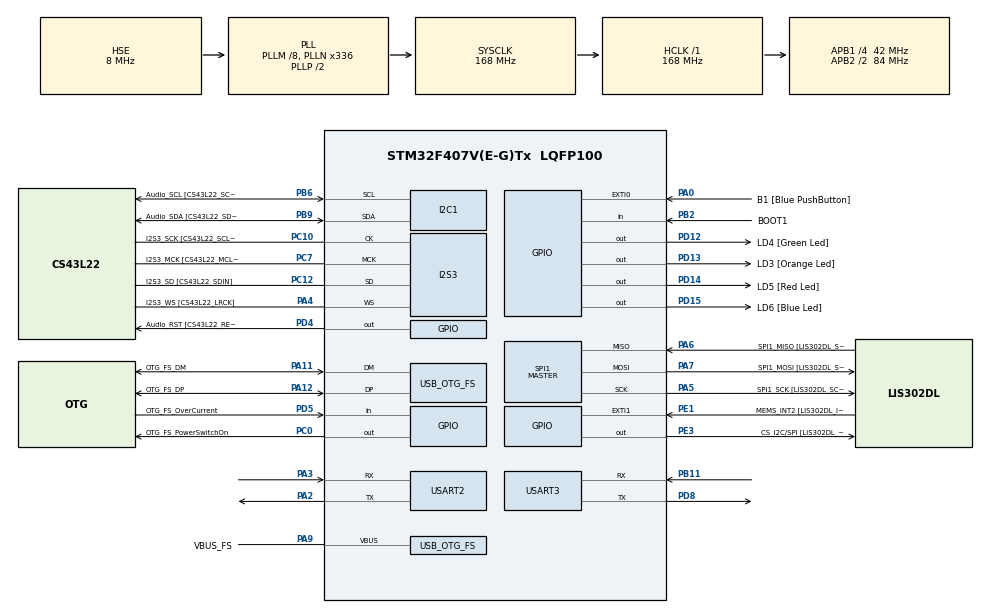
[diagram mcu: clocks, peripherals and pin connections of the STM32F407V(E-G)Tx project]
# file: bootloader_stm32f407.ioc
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I2S3.AudioFreq-Half_Duplex_Master=I2S_AUDIOFREQ_96K
I2S3.ErrorAudioFreq=-2.34 %
I2S3.ErrorAudioFreq-Half_Duplex_Master=0.8 %
I2S3.FullDuplexMode=I2S_FULLDUPLEXMODE_DISABLE
I2S3.Instance=SPI$Index
I2S3.RealAudioFreq=93.75 KHz
I2S3.RealAudioFreq-Half_Duplex_Master=96.774 KHz
I2S3.VirtualMode=I2S_MODE_MASTER
Mcu.Family=STM32F4
Mcu.Name=STM32F407V(E-G)Tx
Mcu.Package=LQFP100
NVIC.OTG_FS_IRQn=true\:0\:0\:false\:false\:true\:true\:true
NVIC.PriorityGroup=NVIC_PRIORITYGROUP_0
PA0-WKUP.GPIO_Label=B1 [Blue PushButton]
PA0-WKUP.GPIO_ModeDefaultEXTI=GPIO_MODE_EVT_RISING
PA0-WKUP.GPIO_PuPd=GPIO_NOPULL
PA0-WKUP.Signal=GPXTI0
PA10.GPIO_Label=OTG_FS_ID
PA10.GPIO_Mode=GPIO_MODE_AF_PP
PA10.GPIO_PuPd=GPIO_NOPULL
PA10.GPIO_Speed=GPIO_SPEED_FREQ_LOW
PA10.Signal=USB_OTG_FS_ID
PA11.GPIO_Label=OTG_FS_DM
PA11.GPIO_Mode=GPIO_MODE_AF_PP
PA11.GPIO_PuPd=GPIO_NOPULL
PA11.GPIO_Speed=GPIO_SPEED_FREQ_LOW
PA11.Mode=Host_Only
PA11.Signal=USB_OTG_FS_DM
PA12.GPIO_Label=OTG_FS_DP
PA12.GPIO_Mode=GPIO_MODE_AF_PP
PA12.GPIO_PuPd=GPIO_NOPULL
PA12.GPIO_Speed=GPIO_SPEED_FREQ_LOW
PA12.Mode=Host_Only
PA12.Signal=USB_OTG_FS_DP
PA13.GPIO_Label=SWDIO
PA13.Mode=Serial_Wire
PA13.Signal=SYS_JTMS-SWDIO
PA14.GPIO_Label=SWCLK
PA14.Mode=Serial_Wire
PA14.Signal=SYS_JTCK-SWCLK
PA2.Mode=Asynchronous
PA2.Signal=USART2_TX
PA3.Mode=Asynchronous
PA3.Signal=USART2_RX
PA4.GPIO_Label=I2S3_WS [CS43L22_LRCK]
PA4.GPIO_Mode=GPIO_MODE_AF_PP
PA4.GPIO_PuPd=GPIO_NOPULL
PA4.GPIO_Speed=GPIO_SPEED_FREQ_LOW
PA4.Mode=Half_Duplex_Master
PA4.Signal=I2S3_WS
PA5.GPIO_Label=SPI1_SCK [LIS302DL_SCL/SPC]
PA5.GPIO_Mode=GPIO_MODE_AF_PP
PA5.GPIO_PuPd=GPIO_NOPULL
PA5.GPIO_Speed=GPIO_SPEED_FREQ_LOW
PA5.Mode=Full_Duplex_Master
PA5.Signal=SPI1_SCK
PA6.GPIO_Label=SPI1_MISO [LIS302DL_SDO]
PA6.GPIO_Mode=GPIO_MODE_AF_PP
PA6.GPIO_PuPd=GPIO_NOPULL
PA6.GPIO_Speed=GPIO_SPEED_FREQ_LOW
PA6.Mode=Full_Duplex_Master
PA6.Signal=SPI1_MISO
PA7.GPIO_Label=SPI1_MOSI [LIS302DL_SDA/SDI/SDO]
PA7.GPIO_Mode=GPIO_MODE_AF_PP
PA7.GPIO_PuPd=GPIO_NOPULL
PA7.GPIO_Speed=GPIO_SPEED_FREQ_LOW
PA7.Mode=Full_Duplex_Master
PA7.Signal=SPI1_MOSI
PA9.GPIO_Label=VBUS_FS
PA9.GPIO_Mode=GPIO_MODE_INPUT
PA9.GPIO_PuPd=GPIO_NOPULL
PA9.Mode=Activate_VBUS
PA9.Signal=USB_OTG_FS_VBUS
PB10.GPIO_Label=CLK_IN [MP45DT02_CLK]
PB10.GPIO_Mode=GPIO_MODE_AF_PP
PB10.GPIO_PuPd=GPIO_NOPULL
PB10.GPIO_Speed=GPIO_SPEED_FREQ_LOW
PB10.Signal=I2S2_CK
PB11.Mode=Asynchronous
PB11.Signal=USART3_RX
PB2.GPIO_Label=BOOT1
PB2.GPIO_Mode=GPIO_MODE_INPUT
PB2.GPIO_PuPd=GPIO_NOPULL
PB2.Signal=GPIO_Input
PB3.GPIO_Label=SWO
PB3.Signal=SYS_JTDO-SWO
PB6.GPIO_Label=Audio_SCL [CS43L22_SCL]
PB6.GPIO_Mode=GPIO_MODE_AF_OD
PB6.GPIO_Pu=GPIO_PULLUP
PB6.GPIO_PuPd=GPIO_NOPULL
PB6.GPIO_Speed=GPIO_SPEED_FREQ_LOW
PB6.Mode=I2C
PB6.Signal=I2C1_SCL
PB9.GPIO_Label=Audio_SDA [CS43L22_SDA]
PB9.GPIO_Mode=GPIO_MODE_AF_OD
PB9.GPIO_Pu=GPIO_PULLUP
PB9.GPIO_PuPd=GPIO_NOPULL
PB9.GPIO_Speed=GPIO_SPEED_FREQ_LOW
PB9.Mode=I2C
PB9.Signal=I2C1_SDA
PC0.GPIO_Label=OTG_FS_PowerSwitchOn
PC0.GPIO_PuPd=GPIO_NOPULL
PC0.GPIO_Speed=GPIO_SPEED_FREQ_LOW
PC0.PinState=GPIO_PIN_SET
PC0.Signal=GPIO_Output
PC10.GPIO_Label=I2S3_SCK [CS43L22_SCLK]
PC10.GPIO_Mode=GPIO_MODE_AF_PP
PC10.GPIO_PuPd=GPIO_NOPULL
PC10.GPIO_Speed=GPIO_SPEED_FREQ_LOW
PC10.Mode=Half_Duplex_Master
PC10.Signal=I2S3_CK
PC12.GPIO_Label=I2S3_SD [CS43L22_SDIN]
PC12.GPIO_Mode=GPIO_MODE_AF_PP
PC12.GPIO_PuPd=GPIO_NOPULL
PC12.GPIO_Speed=GPIO_SPEED_FREQ_LOW
PC12.Mode=Half_Duplex_Master
PC12.Signal=I2S3_SD
PC14-OSC32_IN.GPIO_Label=PC14-OSC32_IN
PC14-OSC32_IN.Mode=LSE-External-Oscillator
PC14-OSC32_IN.Signal=RCC_OSC32_IN
PC15-OSC32_OUT.GPIO_Label=PC15-OSC32_OUT
PC15-OSC32_OUT.Mode=LSE-External-Oscillator
PC15-OSC32_OUT.Signal=RCC_OSC32_OUT
PC3.GPIO_Label=PDM_OUT [MP45DT02_DOUT]
PC3.GPIO_Mode=GPIO_MODE_AF_PP
PC3.GPIO_PuPd=GPIO_NOPULL
PC3.GPIO_Speed=GPIO_SPEED_FREQ_LOW
PC3.Signal=I2S2_SD
PC7.GPIO_Label=I2S3_MCK [CS43L22_MCLK]
PC7.GPIO_Mode=GPIO_MODE_AF_PP
PC7.GPIO_PuPd=GPIO_NOPULL
PC7.GPIO_Speed=GPIO_SPEED_FREQ_LOW
PC7.Mode=Master_Clock_Activated
PC7.Signal=I2S3_MCK
PD12.GPIO_Label=LD4 [Green Led]
PD12.GPIO_PuPd=GPIO_NOPULL
PD12.GPIO_Speed=GPIO_SPEED_FREQ_LOW
PD12.Signal=GPIO_Output
PD13.GPIO_Label=LD3 [Orange Led]
PD13.GPIO_PuPd=GPIO_NOPULL
PD13.GPIO_Speed=GPIO_SPEED_FREQ_LOW
PD13.Signal=GPIO_Output
PD14.GPIO_Label=LD5 [Red Led]
PD14.GPIO_PuPd=GPIO_NOPULL
PD14.GPIO_Speed=GPIO_SPEED_FREQ_LOW
PD14.Signal=GPIO_Output
PD15.GPIO_Label=LD6 [Blue Led]
PD15.GPIO_PuPd=GPIO_NOPULL
PD15.GPIO_Speed=GPIO_SPEED_FREQ_LOW
PD15.Signal=GPIO_Output
PD4.GPIO_Label=Audio_RST [CS43L22_RESET]
PD4.GPIO_PuPd=GPIO_NOPULL
PD4.GPIO_Speed=GPIO_SPEED_FREQ_LOW
PD4.Signal=GPIO_Output
PD5.GPIO_Label=OTG_FS_OverCurrent
PD5.GPIO_Mode=GPIO_MODE_INPUT
PD5.GPIO_PuPd=GPIO_NOPULL
PD5.Signal=GPIO_Input
PD8.Mode=Asynchronous
PD8.Signal=USART3_TX
PE1.GPIO_Label=MEMS_INT2 [LIS302DL_INT2]
PE1.GPIO_ModeDefaultEXTI=GPIO_MODE_EVT_RISING
PE1.GPIO_PuPd=GPIO_NOPULL
PE1.Signal=GPXTI1
PE3.GPIO_Label=CS_I2C/SPI [LIS302DL_CS_I2C/SPI]
PE3.GPIO_PuPd=GPIO_NOPULL
PE3.GPIO_Speed=GPIO_SPEED_FREQ_LOW
PE3.Signal=GPIO_Output
PH0-OSC_IN.GPIO_Label=PH0-OSC_IN
PH0-OSC_IN.Mode=HSE-External-Oscillator
PH0-OSC_IN.Signal=RCC_OSC_IN
PH1-OSC_OUT.GPIO_Label=PH1-OSC_OUT
PH1-OSC_OUT.Mode=HSE-External-Oscillator
PH1-OSC_OUT.Signal=RCC_OSC_OUT
ProjectManager.HeapSize=0x200
ProjectManager.StackSize=0x400
ProjectManager.TargetToolchain=STM32CubeIDE
RCC.48MHZClocksFreq_Value=48000000
RCC.AHBFreq_Value=168000000
RCC.APB1CLKDivider=RCC_HCLK_DIV4
RCC.APB1Freq_Value=42000000
RCC.APB1TimFreq_Value=84000000
RCC.APB2CLKDivider=RCC_HCLK_DIV2
RCC.APB2Freq_Value=84000000
RCC.APB2TimFreq_Value=168000000
RCC.CortexFreq_Value=168000000
RCC.HCLKFreq_Value=168000000
RCC.HSE_VALUE=8000000
RCC.HSI_VALUE=16000000
RCC.PLLM=8
RCC.PLLN=336
RCC.PLLQ=7
RCC.SYSCLKFreq_VALUE=168000000
RCC.SYSCLKSource=RCC_SYSCLKSOURCE_PLLCLK
RCC.VCOOutputFreq_Value=336000000
SPI1.BaudRatePrescaler-Full_Duplex_Master=SPI_BAUDRATEPRESCALER_2
SPI1.CalculateBaudRate-Full_Duplex_Master=42.0 MBits/s
SPI1.Direction=SPI_DIRECTION_2LINES
SPI1.Mode=SPI_MODE_MASTER
SPI1.Mode-Full_Duplex_Master=SPI_MODE_MASTER
SPI1.VirtualType=VM_MASTER
USART2.VirtualMode=VM_ASYNC
USART3.VirtualMode=VM_ASYNC
USB_HOST.BSP.number=1
USB_HOST.USBH_HandleTypeDef-CDC_FS=hUsbHostFS
USB_HOST.VirtualModeFS=Cdc
USB_HOST0.BSP.STBoard=false
USB_HOST0.BSP.api=Unknown
USB_HOST0.BSP.i2caddr=0
USB_HOST0.BSP.i2creg=0
USB_HOST0.BSP.instance=PC0
USB_HOST0.BSP.ip=GPIO
USB_HOST0.BSP.mode=Output
USB_HOST0.BSP.name=Drive_VBUS_FS
USB_HOST0.BSP.solution=PC0
USB_OTG_FS.VirtualMode=Host_Only
USB_OTG_FS.phy_itface=HCD_PHY_EMBEDDED
VP_CRC_VS_CRC.Mode=CRC_Activate
VP_USB_HOST_VS_USB_HOST_CDC_FS.Mode=CDC_FS
board=STM32F407G-DISC1

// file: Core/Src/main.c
/* USER CODE BEGIN Header */
/**
  ******************************************************************************
  * @file           : main.c
  * @brief          : Main program body
  ******************************************************************************
  * @attention
  *
  * <h2><center>&copy; Copyright (c) 2021 STMicroelectronics.
  * All rights reserved.</center></h2>
  *
  * This software component is licensed by ST under Ultimate Liberty license
  * SLA0044, the "License"; You may not use this file except in compliance with
  * the License. You may obtain a copy of the License at:
  *                             www.st.com/SLA0044
  *
  ******************************************************************************
  */
/* USER CODE END Header */
#include <stdarg.h>
#include <string.h>
#include <stdio.h>
#include "main.h"
#include "usb_host.h"

/* USER CODE BEGIN PM */
#define BL_DEBUG_MSG_EN

/* USER CODE END PM */

CRC_HandleTypeDef hcrc;

I2C_HandleTypeDef hi2c1;

I2S_HandleTypeDef hi2s3;

SPI_HandleTypeDef hspi1;

UART_HandleTypeDef huart2;
UART_HandleTypeDef huart3;

uint8_t supported_commands[] = {
								BL_GET_VER,
								BL_GET_HELP,
								BL_GET_CID,
								BL_GET_RDP_STATUS,
								BL_GO_TO_ADDR,
								BL_FLASH_ERASE,
								BL_MEM_WRITE,
								BL_EN_RW_PROTECT,
								BL_MEM_READ,
								BL_READ_SECTOR_P_STATUS,
								BL_OTP_READ,
								BL_DIS_R_W_PROTECT};

#define D_UART &huart3
#define C_UART &huart2
#define BL_RX_LEN 200

void SystemClock_Config(void);
static void MX_GPIO_Init(void);
static void MX_I2C1_Init(void);
static void MX_I2S3_Init(void);
static void MX_SPI1_Init(void);
static void MX_USART2_UART_Init(void);
static void MX_USART3_UART_Init(void);
static void MX_CRC_Init(void);
void MX_USB_HOST_Process(void);

/* USER CODE BEGIN PFP */
static void printmsg(char *format, ...);

/* USER CODE END PFP */

/* USER CODE BEGIN 0 */
char somedata[] = "Hello from Bootloader\r\n";

uint8_t bl_rx_buffer[BL_RX_LEN];

/* USER CODE END 0 */

int main(void)
{

  /* MCU Configuration--------------------------------------------------------*/

  /* Reset of all peripherals, Initializes the Flash interface and the Systick. */
  HAL_Init();

  /* Configure the system clock */
  SystemClock_Config();

  /* Initialize all configured peripherals */
  MX_GPIO_Init();
  MX_I2C1_Init();
  MX_I2S3_Init();
  MX_SPI1_Init();
  MX_USB_HOST_Init();
  MX_USART2_UART_Init();
  MX_USART3_UART_Init();
  MX_CRC_Init();

  /* Let's check whether button is pressed or not, if not pressed jump to user application */
  if (HAL_GPIO_ReadPin(B1_GPIO_Port, B1_Pin) == GPIO_PIN_SET)
  {
	  printmsg("BL_DEBUG_MSG:Button is pressed....going to BL mode\r\n");
	  // we should continue in bootloader mode
	  bootloader_uart_read_data();
  }
  else
  {
	  printmsg("BL_DEBUG_MSG:Button is not pressed....going to app mode\r\n");

	  // we should continue in app mode
	  bootloader_jump_to_app();
  }
}

void bootloader_uart_read_data(void)
{
	uint8_t rcv_len = 0;
	while(1)
	{
		memset(bl_rx_buffer, 0, 200);
		// Here we will read and decode the commands coming from host
		// first read only one byte from the host, which is the length field
		HAL_UART_Receive(C_UART, bl_rx_buffer, 1, HAL_MAX_DELAY);
		rcv_len = (uint8_t) bl_rx_buffer[0];
		HAL_UART_Receive(C_UART, &bl_rx_buffer[1], rcv_len, HAL_MAX_DELAY);
		switch(bl_rx_buffer[1])
		{
			case BL_GET_VER:
				bootloader_handle_getver_cmd(bl_rx_buffer);
				break;
			case BL_GET_HELP:
				bootloader_handle_gethelp_cmd(bl_rx_buffer);
				break;
			case BL_GET_CID:
				bootloader_handle_getcid_cmd(bl_rx_buffer);
				break;
			case BL_GET_RDP_STATUS:
				bootloader_handle_getrdp_cmd(bl_rx_buffer);
				break;
			case BL_GO_TO_ADDR:
				bootloader_handle_go_cmd(bl_rx_buffer);
				break;
			case BL_FLASH_ERASE:
				bootloader_handle_flash_erase_cmd(bl_rx_buffer);
				break;
			case BL_MEM_WRITE:
				bootloader_handle_mem_write_cmd(bl_rx_buffer);
				break;
			case BL_EN_RW_PROTECT:
				bootloader_handle_en_rw_protect(bl_rx_buffer);
				break;
			case BL_DIS_R_W_PROTECT:
                bootloader_handle_dis_rw_protect(bl_rx_buffer);
			case BL_MEM_READ:
				bootloader_handle_mem_read(bl_rx_buffer);
				break;
			case BL_READ_SECTOR_P_STATUS:
				bootloader_handle_read_sector_protection_status(bl_rx_buffer);
				break;
			default:
				printmsg("BL_DEBUG_MSG:Invalid command received from host \n");
				break;
		}
	}
}

void bootloader_jump_to_app(void){
	// just a function pointer to hold the address of the reset handler of the user app
	void (*app_reset_handler)(void);

	printmsg("BL_DEBUG_MSG:bootloader_jump_to_app\r\n");

//	__disable_irq();
	// 1. configure the MSP by reading the value from the base address of the sector 2
	uint32_t msp_value = *(__IO uint32_t *) FLASH_SECTOR2_BASE_ADDRESS;

	// This function comes from CMSIS
	__set_MSP(msp_value);

	// SCB->VTOR = FLASH_SECTOR1_BASE_ADDRESS

	// 2. Now fetch the reset handler address of the user application from the location FLASH_SECTOR2_BASE_ADDRESS
	uint32_t resethandler_address = *(__IO uint32_t *) (FLASH_SECTOR2_BASE_ADDRESS + 4);

	app_reset_handler = (void (*) (void)) resethandler_address;

	printmsg("BL_DEBUG_MSG:app reset handler address: %#x\r\n", app_reset_handler);

//	__enable_irq();
	// 3. Jump to reset handler of the application
	app_reset_handler();
}

/* prints formatted string to console over UART */
void printmsg(char *format, ...)
{
#ifdef BL_DEBUG_MSG_EN
	char str[80];
	/*Extract the argument list using VA pins */
	va_list args;
	va_start(args, format);
	vsprintf(str, format, args);
	HAL_UART_Transmit(D_UART, (uint8_t *) str, strlen(str), HAL_MAX_DELAY);
	va_end(args);
#endif
}

void SystemClock_Config(void)
{
  RCC_OscInitTypeDef RCC_OscInitStruct = {0};
  RCC_ClkInitTypeDef RCC_ClkInitStruct = {0};

  /** Configure the main internal regulator output voltage
  */
  __HAL_RCC_PWR_CLK_ENABLE();
  __HAL_PWR_VOLTAGESCALING_CONFIG(PWR_REGULATOR_VOLTAGE_SCALE1);
  /** Initializes the RCC Oscillators according to the specified parameters
  * in the RCC_OscInitTypeDef structure.
  */
  RCC_OscInitStruct.OscillatorType = RCC_OSCILLATORTYPE_HSE;
  RCC_OscInitStruct.HSEState = RCC_HSE_ON;
  RCC_OscInitStruct.PLL.PLLState = RCC_PLL_ON;
  RCC_OscInitStruct.PLL.PLLSource = RCC_PLLSOURCE_HSE;
  RCC_OscInitStruct.PLL.PLLM = 8;
  RCC_OscInitStruct.PLL.PLLN = 336;
  RCC_OscInitStruct.PLL.PLLP = RCC_PLLP_DIV2;
  RCC_OscInitStruct.PLL.PLLQ = 7;
  if (HAL_RCC_OscConfig(&RCC_OscInitStruct) != HAL_OK)
  {
    Error_Handler();
  }
  /** Initializes the CPU, AHB and APB buses clocks
  */
  RCC_ClkInitStruct.ClockType = RCC_CLOCKTYPE_HCLK|RCC_CLOCKTYPE_SYSCLK
                              |RCC_CLOCKTYPE_PCLK1|RCC_CLOCKTYPE_PCLK2;
  RCC_ClkInitStruct.SYSCLKSource = RCC_SYSCLKSOURCE_PLLCLK;
  RCC_ClkInitStruct.AHBCLKDivider = RCC_SYSCLK_DIV1;
  RCC_ClkInitStruct.APB1CLKDivider = RCC_HCLK_DIV4;
  RCC_ClkInitStruct.APB2CLKDivider = RCC_HCLK_DIV2;

  if (HAL_RCC_ClockConfig(&RCC_ClkInitStruct, FLASH_LATENCY_5) != HAL_OK)
  {
    Error_Handler();
  }
}

static void MX_CRC_Init(void)
{

  hcrc.Instance = CRC;
  if (HAL_CRC_Init(&hcrc) != HAL_OK)
  {
    Error_Handler();
  }

}

static void MX_I2C1_Init(void)
{

  hi2c1.Instance = I2C1;
  hi2c1.Init.ClockSpeed = 100000;
  hi2c1.Init.DutyCycle = I2C_DUTYCYCLE_2;
  hi2c1.Init.OwnAddress1 = 0;
  hi2c1.Init.AddressingMode = I2C_ADDRESSINGMODE_7BIT;
  hi2c1.Init.DualAddressMode = I2C_DUALADDRESS_DISABLE;
  hi2c1.Init.OwnAddress2 = 0;
  hi2c1.Init.GeneralCallMode = I2C_GENERALCALL_DISABLE;
  hi2c1.Init.NoStretchMode = I2C_NOSTRETCH_DISABLE;
  if (HAL_I2C_Init(&hi2c1) != HAL_OK)
  {
    Error_Handler();
  }

}

static void MX_I2S3_Init(void)
{

  hi2s3.Instance = SPI3;
  hi2s3.Init.Mode = I2S_MODE_MASTER_TX;
  hi2s3.Init.Standard = I2S_STANDARD_PHILIPS;
  hi2s3.Init.DataFormat = I2S_DATAFORMAT_16B;
  hi2s3.Init.MCLKOutput = I2S_MCLKOUTPUT_ENABLE;
  hi2s3.Init.AudioFreq = I2S_AUDIOFREQ_96K;
  hi2s3.Init.CPOL = I2S_CPOL_LOW;
  hi2s3.Init.ClockSource = I2S_CLOCK_PLL;
  hi2s3.Init.FullDuplexMode = I2S_FULLDUPLEXMODE_DISABLE;
  if (HAL_I2S_Init(&hi2s3) != HAL_OK)
  {
    Error_Handler();
  }

}

static void MX_SPI1_Init(void)
{

  /* SPI1 parameter configuration*/
  hspi1.Instance = SPI1;
  hspi1.Init.Mode = SPI_MODE_MASTER;
  hspi1.Init.Direction = SPI_DIRECTION_2LINES;
  hspi1.Init.DataSize = SPI_DATASIZE_8BIT;
  hspi1.Init.CLKPolarity = SPI_POLARITY_LOW;
  hspi1.Init.CLKPhase = SPI_PHASE_1EDGE;
  hspi1.Init.NSS = SPI_NSS_SOFT;
  hspi1.Init.BaudRatePrescaler = SPI_BAUDRATEPRESCALER_2;
  hspi1.Init.FirstBit = SPI_FIRSTBIT_MSB;
  hspi1.Init.TIMode = SPI_TIMODE_DISABLE;
  hspi1.Init.CRCCalculation = SPI_CRCCALCULATION_DISABLE;
  hspi1.Init.CRCPolynomial = 10;
  if (HAL_SPI_Init(&hspi1) != HAL_OK)
  {
    Error_Handler();
  }

}

static void MX_USART2_UART_Init(void)
{

  huart2.Instance = USART2;
  huart2.Init.BaudRate = 115200;
  huart2.Init.WordLength = UART_WORDLENGTH_8B;
  huart2.Init.StopBits = UART_STOPBITS_1;
  huart2.Init.Parity = UART_PARITY_NONE;
  huart2.Init.Mode = UART_MODE_TX_RX;
  huart2.Init.HwFlowCtl = UART_HWCONTROL_NONE;
  huart2.Init.OverSampling = UART_OVERSAMPLING_16;
  if (HAL_UART_Init(&huart2) != HAL_OK)
  {
    Error_Handler();
  }

}

static void MX_USART3_UART_Init(void)
{

  huart3.Instance = USART3;
  huart3.Init.BaudRate = 115200;
  huart3.Init.WordLength = UART_WORDLENGTH_8B;
  huart3.Init.StopBits = UART_STOPBITS_1;
  huart3.Init.Parity = UART_PARITY_NONE;
  huart3.Init.Mode = UART_MODE_TX_RX;
  huart3.Init.HwFlowCtl = UART_HWCONTROL_NONE;
  huart3.Init.OverSampling = UART_OVERSAMPLING_16;
  if (HAL_UART_Init(&huart3) != HAL_OK)
  {
    Error_Handler();
  }

}

static void MX_GPIO_Init(void)
{
  GPIO_InitTypeDef GPIO_InitStruct = {0};

  /* GPIO Ports Clock Enable */
  __HAL_RCC_GPIOE_CLK_ENABLE();
  __HAL_RCC_GPIOC_CLK_ENABLE();
  __HAL_RCC_GPIOH_CLK_ENABLE();
  __HAL_RCC_GPIOA_CLK_ENABLE();
  __HAL_RCC_GPIOB_CLK_ENABLE();
  __HAL_RCC_GPIOD_CLK_ENABLE();

  /*Configure GPIO pin Output Level */
  HAL_GPIO_WritePin(CS_I2C_SPI_GPIO_Port, CS_I2C_SPI_Pin, GPIO_PIN_RESET);

  /*Configure GPIO pin Output Level */
  HAL_GPIO_WritePin(OTG_FS_PowerSwitchOn_GPIO_Port, OTG_FS_PowerSwitchOn_Pin, GPIO_PIN_SET);

  /*Configure GPIO pin Output Level */
  HAL_GPIO_WritePin(GPIOD, LD4_Pin|LD3_Pin|LD5_Pin|LD6_Pin
                          |Audio_RST_Pin, GPIO_PIN_RESET);

  /*Configure GPIO pin : CS_I2C_SPI_Pin */
  GPIO_InitStruct.Pin = CS_I2C_SPI_Pin;
  GPIO_InitStruct.Mode = GPIO_MODE_OUTPUT_PP;
  GPIO_InitStruct.Pull = GPIO_NOPULL;
  GPIO_InitStruct.Speed = GPIO_SPEED_FREQ_LOW;
  HAL_GPIO_Init(CS_I2C_SPI_GPIO_Port, &GPIO_InitStruct);

  /*Configure GPIO pin : OTG_FS_PowerSwitchOn_Pin */
  GPIO_InitStruct.Pin = OTG_FS_PowerSwitchOn_Pin;
  GPIO_InitStruct.Mode = GPIO_MODE_OUTPUT_PP;
  GPIO_InitStruct.Pull = GPIO_NOPULL;
  GPIO_InitStruct.Speed = GPIO_SPEED_FREQ_LOW;
  HAL_GPIO_Init(OTG_FS_PowerSwitchOn_GPIO_Port, &GPIO_InitStruct);

  /*Configure GPIO pin : PDM_OUT_Pin */
  GPIO_InitStruct.Pin = PDM_OUT_Pin;
  GPIO_InitStruct.Mode = GPIO_MODE_AF_PP;
  GPIO_InitStruct.Pull = GPIO_NOPULL;
  GPIO_InitStruct.Speed = GPIO_SPEED_FREQ_LOW;
  GPIO_InitStruct.Alternate = GPIO_AF5_SPI2;
  HAL_GPIO_Init(PDM_OUT_GPIO_Port, &GPIO_InitStruct);

  /*Configure GPIO pin : B1_Pin */
  GPIO_InitStruct.Pin = B1_Pin;
  GPIO_InitStruct.Mode = GPIO_MODE_EVT_RISING;
  GPIO_InitStruct.Pull = GPIO_NOPULL;
  HAL_GPIO_Init(B1_GPIO_Port, &GPIO_InitStruct);

  /*Configure GPIO pin : BOOT1_Pin */
  GPIO_InitStruct.Pin = BOOT1_Pin;
  GPIO_InitStruct.Mode = GPIO_MODE_INPUT;
  GPIO_InitStruct.Pull = GPIO_NOPULL;
  HAL_GPIO_Init(BOOT1_GPIO_Port, &GPIO_InitStruct);

  /*Configure GPIO pin : CLK_IN_Pin */
  GPIO_InitStruct.Pin = CLK_IN_Pin;
  GPIO_InitStruct.Mode = GPIO_MODE_AF_PP;
  GPIO_InitStruct.Pull = GPIO_NOPULL;
  GPIO_InitStruct.Speed = GPIO_SPEED_FREQ_LOW;
  GPIO_InitStruct.Alternate = GPIO_AF5_SPI2;
  HAL_GPIO_Init(CLK_IN_GPIO_Port, &GPIO_InitStruct);

  /*Configure GPIO pins : LD4_Pin LD3_Pin LD5_Pin LD6_Pin
                           Audio_RST_Pin */
  GPIO_InitStruct.Pin = LD4_Pin|LD3_Pin|LD5_Pin|LD6_Pin
                          |Audio_RST_Pin;
  GPIO_InitStruct.Mode = GPIO_MODE_OUTPUT_PP;
  GPIO_InitStruct.Pull = GPIO_NOPULL;
  GPIO_InitStruct.Speed = GPIO_SPEED_FREQ_LOW;
  HAL_GPIO_Init(GPIOD, &GPIO_InitStruct);

  /*Configure GPIO pin : OTG_FS_OverCurrent_Pin */
  GPIO_InitStruct.Pin = OTG_FS_OverCurrent_Pin;
  GPIO_InitStruct.Mode = GPIO_MODE_INPUT;
  GPIO_InitStruct.Pull = GPIO_NOPULL;
  HAL_GPIO_Init(OTG_FS_OverCurrent_GPIO_Port, &GPIO_InitStruct);

  /*Configure GPIO pin : MEMS_INT2_Pin */
  GPIO_InitStruct.Pin = MEMS_INT2_Pin;
  GPIO_InitStruct.Mode = GPIO_MODE_EVT_RISING;
  GPIO_InitStruct.Pull = GPIO_NOPULL;
  HAL_GPIO_Init(MEMS_INT2_GPIO_Port, &GPIO_InitStruct);

}

/********* Implementation of Bootloader command handle functions *********************/
void bootloader_handle_gethelp_cmd(uint8_t *pBuffer)
{
	// 1. verify the checksum
	printmsg("BL_DEBUG_MSG: bootloader_handle_gethelp_cmd \r\n");

	// Total length of the command packet
	uint32_t command_packet_len = pBuffer[0] + 1;

	// Extract the CRC32 sent by the Host
	uint32_t host_crc = *((uint32_t *) (pBuffer + command_packet_len - 4));

	if(!bootloader_verify_crc(&pBuffer[0], command_packet_len - 4, host_crc))
	{
		printmsg("BL_DEBUG_MSG: checksum success !! \r\n");
		// checksum is correct
		bootloader_send_ack(pBuffer[0], sizeof(supported_commands));
		bootloader_uart_write_data(supported_commands, sizeof(supported_commands));
	}
	else
	{
		printmsg("BL_DEBUG_MSG: checksum fail !! \r\n");
		// checksum is wrong send neck
		bootloader_send_nack();
	}
}

void bootloader_handle_getver_cmd(uint8_t *bl_rx_buffer)
{
	uint8_t bl_version;
	printmsg("BL_DEBUG_MSG: bootloader_handle_getver_cmd \r\n");

	// Total length of the command packet
	uint32_t command_packet_len = bl_rx_buffer[0] + 1;

	// Extract the CRC32 sent by the Host
	uint32_t host_crc = *((uint32_t *) (bl_rx_buffer + command_packet_len - 4));

	if(!bootloader_verify_crc(&bl_rx_buffer[0], command_packet_len - 4, host_crc))
	{
		printmsg("BL_DEBUG_MSG:checksum success !! \r\n");
		// checksum is correct
		bootloader_send_ack(bl_rx_buffer[0], 1);
		bl_version = get_bootloader_version();
		printmsg("BL_DEBUG_MSG:BL_VER : %d %#x", bl_version, bl_version);
		bootloader_uart_write_data(&bl_version, 1);
	}
	else
	{
		printmsg("BL_DEBUG_MSG: checksum fail !! \r\n");
		// checksum is wrong send neck
		bootloader_send_nack();
	}
}

void bootloader_handle_getcid_cmd(uint8_t *pBuffer)
{
	uint16_t bl_cid_num;
	// 1. verify the checksum
	printmsg("BL_DEBUG_MSG: bootloader_handle_getcid_cmd \r\n");

	// Total length of the command packet
	uint32_t command_packet_len = pBuffer[0] + 1;

	// Extract the CRC32 sent by the Host
	uint32_t host_crc = *((uint32_t *) (pBuffer + command_packet_len - 4));

	if(!bootloader_verify_crc(&pBuffer[0], command_packet_len - 4, host_crc))
	{
		printmsg("BL_DEBUG_MSG: checksum success !! \r\n");
		// checksum is correct
		bootloader_send_ack(pBuffer[0], 2);
		bl_cid_num = get_mcu_chip_id();
		printmsg("BL_DEBUG_MSG: MCU id : %d %#x !! \r\n", bl_cid_num, bl_cid_num);
		bootloader_uart_write_data((uint8_t *) &bl_cid_num, 2);
	}
	else
	{
		printmsg("BL_DEBUG_MSG: checksum fail !! \r\n");
		// checksum is wrong send neck
		bootloader_send_nack();
	}
}

void bootloader_handle_getrdp_cmd(uint8_t *pBuffer)
{
	uint8_t rdp_level = 0x00;
	// 1. verify the checksum
	printmsg("BL_DEBUG_MSG: bootloader_handle_getrdp_cmd \r\n");

	// Total length of the command packet
	uint32_t command_packet_len = pBuffer[0] + 1;

	// Extract the CRC32 sent by the Host
	uint32_t host_crc = *((uint32_t *) (pBuffer + command_packet_len - 4));

	if(!bootloader_verify_crc(&pBuffer[0], command_packet_len - 4, host_crc))
	{
		printmsg("BL_DEBUG_MSG: checksum success !! \r\n");
		// checksum is correct
		bootloader_send_ack(pBuffer[0], 1);
		rdp_level = get_flash_rdp_level();
		printmsg("BL_DEBUG_MSG: RDP level : %d %#x !! \r\n", rdp_level, rdp_level);
		bootloader_uart_write_data(&rdp_level, 1);
	}
	else
	{
		printmsg("BL_DEBUG_MSG: checksum fail !! \r\n");
		// checksum is wrong send neck
		bootloader_send_nack();
	}

}

void bootloader_handle_go_cmd(uint8_t *pBuffer)
{
    uint32_t go_address=0;
    uint8_t addr_valid = ADDR_VALID;
    uint8_t addr_invalid = ADDR_INVALID;

    printmsg("BL_DEBUG_MSG:bootloader_handle_go_cmd\n");

    //Total length of the command packet
	uint32_t command_packet_len = pBuffer[0]+1 ;

	//extract the CRC32 sent by the Host
	uint32_t host_crc = *((uint32_t * ) (pBuffer+command_packet_len - 4) ) ;

	if (!bootloader_verify_crc(&pBuffer[0],command_packet_len-4,host_crc))
	{
        printmsg("BL_DEBUG_MSG:checksum success !!\n");

        bootloader_send_ack(pBuffer[0],1);

        //extract the go address
        go_address = *((uint32_t *)&pBuffer[2] );
        printmsg("BL_DEBUG_MSG:GO addr: %#x\n",go_address);

        if( verify_address(go_address) == ADDR_VALID )
        {
            //tell host that address is fine
            bootloader_uart_write_data(&addr_valid,1);

            /*jump to "go" address.
            we dont care what is being done there.
            host must ensure that valid code is present over there
            Its not the duty of bootloader. so just trust and jump */

            /* Not doing the below line will result in hardfault exception for ARM cortex M */
            //watch : https://www.youtube.com/watch?v=VX_12SjnNhY

//            go_address+=1; //make T bit =1

            void (*lets_jump)(void) = (void *)go_address;

            printmsg("BL_DEBUG_MSG: jumping to go address! \n");

            lets_jump();

		}else
		{
            printmsg("BL_DEBUG_MSG:GO addr invalid ! \n");
            //tell host that address is invalid
            bootloader_uart_write_data(&addr_invalid,1);
		}

	}else
	{
        printmsg("BL_DEBUG_MSG:checksum fail !!\n");
        bootloader_send_nack();
	}
}

void bootloader_handle_flash_erase_cmd(uint8_t *pBuffer)
{
    uint8_t erase_status = 0x00;
    printmsg("BL_DEBUG_MSG:bootloader_handle_flash_erase_cmd\n");

    //Total length of the command packet
	uint32_t command_packet_len = pBuffer[0]+1 ;

	//extract the CRC32 sent by the Host
	uint32_t host_crc = *((uint32_t * ) (pBuffer+command_packet_len - 4) ) ;

	if (! bootloader_verify_crc(&pBuffer[0],command_packet_len-4,host_crc))
	{
        printmsg("BL_DEBUG_MSG:checksum success !!\n");
        bootloader_send_ack(pBuffer[0],1);
        printmsg("BL_DEBUG_MSG:initial_sector : %d  no_ofsectors: %d\n",pBuffer[2],pBuffer[3]);

        HAL_GPIO_WritePin(LD3_GPIO_Port, LD3_Pin,GPIO_PIN_SET);
        erase_status = execute_flash_erase(pBuffer[2] , pBuffer[3]);
        HAL_GPIO_WritePin(LD3_GPIO_Port, LD3_Pin,GPIO_PIN_RESET);

        printmsg("BL_DEBUG_MSG: flash erase status: %#x\n",erase_status);

        bootloader_uart_write_data(&erase_status,1);

	}else
	{
        printmsg("BL_DEBUG_MSG:checksum fail !!\n");
        bootloader_send_nack();
	}

}

/*Helper function to handle BL_MEM_WRITE command */
void bootloader_handle_mem_write_cmd(uint8_t *pBuffer)
{
	uint8_t write_status = 0x00;
	uint8_t payload_len = pBuffer[6];

	uint32_t mem_address = *((uint32_t *) ( &pBuffer[2]) );

    printmsg("BL_DEBUG_MSG:bootloader_handle_mem_write_cmd\n");

    //Total length of the command packet
	uint32_t command_packet_len = pBuffer[0]+1 ;

	//extract the CRC32 sent by the Host
	uint32_t host_crc = *((uint32_t * ) (pBuffer+command_packet_len - 4) ) ;

	if (! bootloader_verify_crc(&bl_rx_buffer[0],command_packet_len-4,host_crc))
	{
        printmsg("BL_DEBUG_MSG:checksum success !!\n");

        bootloader_send_ack(pBuffer[0],1);

        printmsg("BL_DEBUG_MSG: mem write address : %#x\n",mem_address);

		if( verify_address(mem_address) == ADDR_VALID )
		{

            printmsg("BL_DEBUG_MSG: valid mem write address\n");

            //glow the led to indicate bootloader is currently writing to memory
            HAL_GPIO_WritePin(LD3_GPIO_Port, LD3_Pin, GPIO_PIN_SET);

            //execute mem write
            write_status = execute_mem_write(&pBuffer[7], mem_address, payload_len);

            //turn off the led to indicate memory write is over
            HAL_GPIO_WritePin(LD3_GPIO_Port, LD3_Pin, GPIO_PIN_RESET);

            //inform host about the status
            bootloader_uart_write_data(&write_status,1);

		}else
		{
            printmsg("BL_DEBUG_MSG: invalid mem write address\n");
            write_status = ADDR_INVALID;
            //inform host that address is invalid
            bootloader_uart_write_data(&write_status,1);
		}

	}else
	{
        printmsg("BL_DEBUG_MSG:checksum fail !!\n");
        bootloader_send_nack();
	}

}

/*Helper function to handle BL_EN_RW_PROTECT  command */
void bootloader_handle_en_rw_protect(uint8_t *pBuffer)
{
    uint8_t status = 0x00;
    printmsg("BL_DEBUG_MSG:bootloader_handle_endis_rw_protect\n");

    //Total length of the command packet
	uint32_t command_packet_len = pBuffer[0]+1 ;

	//extract the CRC32 sent by the Host
	uint32_t host_crc = *((uint32_t * ) (pBuffer+command_packet_len - 4) ) ;

	if (! bootloader_verify_crc(&pBuffer[0],command_packet_len-4,host_crc))
	{
        printmsg("BL_DEBUG_MSG:checksum success !!\n");
        bootloader_send_ack(pBuffer[0],1);

        status = configure_flash_sector_rw_protection(pBuffer[2] , pBuffer[3], 0);

        printmsg("BL_DEBUG_MSG: flash erase status: %#x\n",status);

        bootloader_uart_write_data(&status,1);

	}else
	{
        printmsg("BL_DEBUG_MSG:checksum fail !!\n");
        bootloader_send_nack();
	}

}

/*Helper function to handle BL_EN_RW_PROTECT  command */
void bootloader_handle_dis_rw_protect(uint8_t *pBuffer)
{
    uint8_t status = 0x00;
    printmsg("BL_DEBUG_MSG:bootloader_handle_dis_rw_protect\n");

    //Total length of the command packet
	uint32_t command_packet_len = pBuffer[0]+1 ;

	//extract the CRC32 sent by the Host
	uint32_t host_crc = *((uint32_t * ) (pBuffer+command_packet_len - 4) ) ;

	if (! bootloader_verify_crc(&pBuffer[0],command_packet_len-4,host_crc))
	{
        printmsg("BL_DEBUG_MSG:checksum success !!\n");
        bootloader_send_ack(pBuffer[0],1);

        status = configure_flash_sector_rw_protection(0,0,1);

        printmsg("BL_DEBUG_MSG: flash erase status: %#x\n",status);

        bootloader_uart_write_data(&status,1);

	}else
	{
        printmsg("BL_DEBUG_MSG:checksum fail !!\n");
        bootloader_send_nack();
	}

}

void bootloader_handle_mem_read(uint8_t *bl_rx_buffer)
{

}

/*Helper function to handle _BL_READ_SECTOR_P_STATUS command */
void bootloader_handle_read_sector_protection_status(uint8_t *pBuffer)
{
	uint16_t status;
	printmsg("BL_DEBUG_MSG:bootloader_handle_read_sector_protection_status\n");

    //Total length of the command packet
	uint32_t command_packet_len = bl_rx_buffer[0]+1 ;

	//extract the CRC32 sent by the Host
	uint32_t host_crc = *((uint32_t * ) (bl_rx_buffer+command_packet_len - 4) ) ;

	if (! bootloader_verify_crc(&bl_rx_buffer[0],command_packet_len-4,host_crc))
	{
        printmsg("BL_DEBUG_MSG:checksum success !!\n");
        bootloader_send_ack(pBuffer[0],2);
        status=read_OB_rw_protection_status();
        printmsg("BL_DEBUG_MSG: nWRP status: %#x\n",status);
        bootloader_uart_write_data((uint8_t*)&status,2);

	}else
	{
        printmsg("BL_DEBUG_MSG:checksum fail !!\n");
        bootloader_send_nack();
	}

}

void bootloader_handle_read_otp(uint8_t *bl_rx_buffer)
{

}

uint8_t get_bootloader_version(void)
{
	return (uint8_t) BL_VERSION;
}

void bootloader_uart_write_data(uint8_t *pBuffer, uint32_t len)
{
	HAL_UART_Transmit(C_UART, pBuffer, len, HAL_MAX_DELAY);
}

//This verifies the CRC of the given buffer in pData .
uint8_t bootloader_verify_crc (uint8_t *pData, uint32_t len, uint32_t crc_host)
{
    uint32_t uwCRCValue=0xff;

    for (uint32_t i=0 ; i < len ; i++)
	{
        uint32_t i_data = pData[i];
        uwCRCValue = HAL_CRC_Accumulate(&hcrc, &i_data, 1);
	}

	 /* Reset CRC Calculation Unit */
    __HAL_CRC_DR_RESET(&hcrc);

	if( uwCRCValue == crc_host)
	{
		return VERIFY_CRC_SUCCESS;
	}

	return VERIFY_CRC_FAIL;
}

/* This function sends ACK if CRC matches along with "len to follow" */
void bootloader_send_ack(uint8_t command_code, uint8_t follow_len)
{
	// here we send 2 bytes...first byte is ack and second byte is len value
	uint8_t ack_buff[2];
	ack_buff[0] = BL_ACK;
	ack_buff[1] = follow_len;
	HAL_UART_Transmit(C_UART, ack_buff, 2, HAL_MAX_DELAY);
}

void bootloader_send_nack(void)
{
	uint8_t nack = BL_NACK;
	HAL_UART_Transmit(C_UART, &nack, 1, HAL_MAX_DELAY);
}

uint16_t get_mcu_chip_id(void)
{
	uint16_t cid;
	cid = (uint16_t) (DBGMCU -> IDCODE) & 0x0FFF;
	return cid;
}

uint8_t get_flash_rdp_level(void)
{
	uint8_t rdp_status = 0;
#if 0
	// use the HAL Flash API to get the rdp level
	FLASH_OBProgramInitTypeDef ob_handle;
	HAL_FLASHEx_OBGetConfig(&ob_handle);
	rdp_status = (uint8_t) ob_handle.RDPLevel;
#else
	volatile uint32_t *pOB_addr = (uint32_t*) 0x1FFFC000;
	rdp_status = (uint8_t)(*pOB_addr >> 8);
#endif
	return rdp_status;
}

//verify the address sent by the host .
uint8_t verify_address(uint32_t go_address)
{
	//so, what are the valid addresses to which we can jump ?
	//can we jump to system memory ? yes
	//can we jump to sram1 memory ?  yes
	//can we jump to sram2 memory ? yes
	//can we jump to backup sram memory ? yes
	//can we jump to peripheral memory ? its possible , but dont allow. so no
	//can we jump to external memory ? yes.

//incomplete -poorly written .. optimize it
	if ( go_address >= SRAM1_BASE && go_address <= SRAM1_END)
	{
		return ADDR_VALID;
	}
	else if ( go_address >= SRAM2_BASE && go_address <= SRAM2_END)
	{
		return ADDR_VALID;
	}
	else if ( go_address >= FLASH_BASE && go_address <= FLASH_END)
	{
		return ADDR_VALID;
	}
	else if ( go_address >= BKPSRAM_BASE && go_address <= BKPSRAM_END)
	{
		return ADDR_VALID;
	}
	else
		return ADDR_INVALID;
}

uint8_t execute_flash_erase(uint8_t sector_number , uint8_t number_of_sector)
{
    //we have totally 12 sectors in STM32F407 mcu .. sector[0 to 11]
	//number_of_sector has to be in the range of 0 to 11
	//if sector_number = 0xff , that means mass erase !
	//Code needs to modified if your MCU supports more flash sectors
	FLASH_EraseInitTypeDef flashErase_handle;
	uint32_t sectorError;
	HAL_StatusTypeDef status;

	if( number_of_sector > 12 )
		return INVALID_SECTOR;

	if( (sector_number == 0xff ) || (sector_number <= 11) )
	{
		if(sector_number == (uint8_t) 0xff)
		{
			flashErase_handle.TypeErase = FLASH_TYPEERASE_MASSERASE;
		}else
		{
		    /*Here we are just calculating how many sectors needs to erased */
			uint8_t remanining_sector = 12 - sector_number;
           if( number_of_sector > remanining_sector)
           {
           	number_of_sector = remanining_sector;
           }
			flashErase_handle.TypeErase = FLASH_TYPEERASE_SECTORS;
			flashErase_handle.Sector = sector_number; // this is the initial sector
			flashErase_handle.NbSectors = number_of_sector;
		}
		flashErase_handle.Banks = FLASH_BANK_1;

		/*Get access to touch the flash registers */
		HAL_FLASH_Unlock();
		flashErase_handle.VoltageRange = FLASH_VOLTAGE_RANGE_3;  // our mcu will work on this voltage range
		status = (uint8_t) HAL_FLASHEx_Erase(&flashErase_handle, &sectorError);
		HAL_FLASH_Lock();

		return status;
	}

	return INVALID_SECTOR;
}

/*This function writes the contents of pBuffer to  "mem_address" byte by byte */
//Note1 : Currently this function supports writing to Flash only .
//Note2 : This functions does not check whether "mem_address" is a valid address of the flash range.
uint8_t execute_mem_write(uint8_t *pBuffer, uint32_t mem_address, uint32_t len)
{
    uint8_t status=HAL_OK;

    //We have to unlock flash module to get control of registers
    HAL_FLASH_Unlock();

    for(uint32_t i = 0 ; i <len ; i++)
    {
        //Here we program the flash byte by byte
        status = HAL_FLASH_Program(FLASH_TYPEPROGRAM_BYTE,mem_address+i,pBuffer[i] );
    }

    HAL_FLASH_Lock();

    return status;
}

/*
Modifying user option bytes
To modify the user option value, follow the sequence below:
1. Check that no Flash memory operation is ongoing by checking the BSY bit in the
FLASH_SR register
2. Write the desired option value in the FLASH_OPTCR register.
3. Set the option start bit (OPTSTRT) in the FLASH_OPTCR register
4. Wait for the BSY bit to be cleared.
*/
uint8_t configure_flash_sector_rw_protection(uint8_t sector_details, uint8_t protection_mode, uint8_t disable)
{
    //First configure the protection mode
    //protection_mode =1 , means write protect of the user flash sectors
    //protection_mode =2, means read/write protect of the user flash sectors
    //According to RM of stm32f446xx TABLE 9, We have to modify the address 0x1FFF C008 bit 15(SPRMOD)

	 //Flash option control register (OPTCR)
    volatile uint32_t *pOPTCR = (uint32_t*) 0x40023C14;

	  if(disable)
		{
			//disable all r/w protection on sectors

			//Option byte configuration unlock
			HAL_FLASH_OB_Unlock();

			//wait till no active operation on flash
			while(__HAL_FLASH_GET_FLAG(FLASH_FLAG_BSY) != RESET);

			//clear the 31st bit (default state)
			//please refer : Flash option control register (FLASH_OPTCR) in RM
			*pOPTCR &= ~(1 << 31);

			//clear the protection : make all bits belonging to sectors as 1
			*pOPTCR |= (0xFF << 16);

			//Set the option start bit (OPTSTRT) in the FLASH_OPTCR register
			*pOPTCR |= ( 1 << 1);

			//wait till no active operation on flash
			while(__HAL_FLASH_GET_FLAG(FLASH_FLAG_BSY) != RESET);

			HAL_FLASH_OB_Lock();

			return 0;

		}

	   if(protection_mode == (uint8_t) 1)
    {
           //we are putting write protection on the sectors encoded in sector_details argument

			//Option byte configuration unlock
			HAL_FLASH_OB_Unlock();

			//wait till no active operation on flash
			while(__HAL_FLASH_GET_FLAG(FLASH_FLAG_BSY) != RESET);

			//here we are setting just write protection for the sectors
			//clear the 31st bit
			//please refer : Flash option control register (FLASH_OPTCR) in RM
			*pOPTCR &= ~(1 << 31);

			//put write protection on sectors
			*pOPTCR &= ~ (sector_details << 16);

			//Set the option start bit (OPTSTRT) in the FLASH_OPTCR register
			*pOPTCR |= ( 1 << 1);

			//wait till no active operation on flash
			while(__HAL_FLASH_GET_FLAG(FLASH_FLAG_BSY) != RESET);

			HAL_FLASH_OB_Lock();
		}

		else if (protection_mode == (uint8_t) 2)
    {
	  	//Option byte configuration unlock
			HAL_FLASH_OB_Unlock();

			//wait till no active operation on flash
			while(__HAL_FLASH_GET_FLAG(FLASH_FLAG_BSY) != RESET);

			//here wer are setting read and write protection for the sectors
			//set the 31st bit
			//please refer : Flash option control register (FLASH_OPTCR) in RM
			*pOPTCR |= (1 << 31);

			//put read and write protection on sectors
            *pOPTCR &= ~(0xff << 16);
			*pOPTCR |= (sector_details << 16);

			//Set the option start bit (OPTSTRT) in the FLASH_OPTCR register
			*pOPTCR |= ( 1 << 1);

			//wait till no active operation on flash
			while(__HAL_FLASH_GET_FLAG(FLASH_FLAG_BSY) != RESET);

			HAL_FLASH_OB_Lock();
    }

		return 0;
}

uint16_t read_OB_rw_protection_status(void)
{
    //This structure is given by ST Flash driver to hold the OB(Option Byte) contents .
	FLASH_OBProgramInitTypeDef OBInit;

	//First unlock the OB(Option Byte) memory access
	HAL_FLASH_OB_Unlock();
	//get the OB configuration details
	HAL_FLASHEx_OBGetConfig(&OBInit);
	//Lock back .
	HAL_FLASH_Lock();

	//We are just interested in r/w protection status of the sectors.
	return (uint16_t)OBInit.WRPSector;

}

void Error_Handler(void)
{
  __disable_irq();
  while (1)
  {
  }
}

/************************ (C) COPYRIGHT STMicroelectronics *****END OF FILE****/
